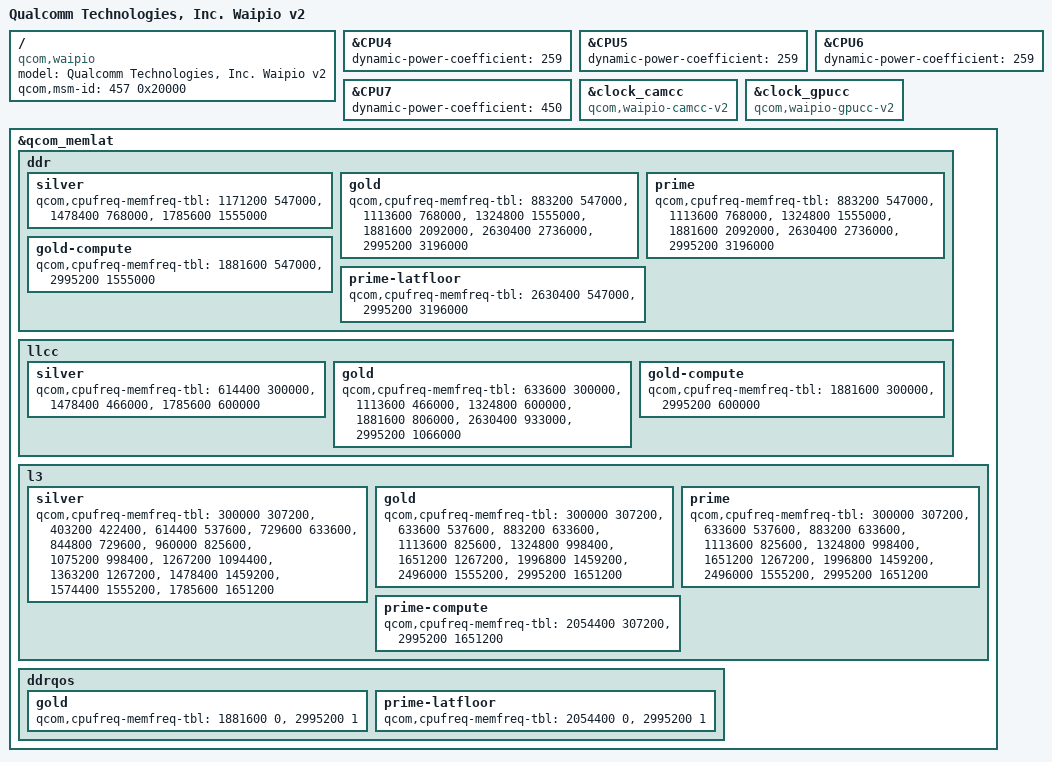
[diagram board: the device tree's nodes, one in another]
#include "waipio.dtsi"

/ {
	model = "Qualcomm Technologies, Inc. Waipio v2";
	compatible = "qcom,waipio";
	qcom,msm-id = <457 0x20000>;
};

&CPU4 {
	dynamic-power-coefficient = <259>;
};

&CPU5 {
	dynamic-power-coefficient = <259>;
};

&CPU6 {
	dynamic-power-coefficient = <259>;
};

&CPU7 {
	dynamic-power-coefficient = <450>;
};

&clock_camcc {
	compatible = "qcom,waipio-camcc-v2", "syscon";
};

&clock_gpucc {
	compatible = "qcom,waipio-gpucc-v2", "syscon";
};

&qcom_memlat {
	ddr {
		silver {
			qcom,cpufreq-memfreq-tbl =
				< 1171200  547000 >,
				< 1478400  768000 >,
				< 1785600 1555000 >;
		};

		gold {
			qcom,cpufreq-memfreq-tbl =
				<  883200  547000 >,
				< 1113600  768000 >,
				< 1324800 1555000 >,
				< 1881600 2092000 >,
				< 2630400 2736000 >,
				< 2995200 3196000 >;
		};

		prime {
			qcom,cpufreq-memfreq-tbl =
				<  883200  547000 >,
				< 1113600  768000 >,
				< 1324800 1555000 >,
				< 1881600 2092000 >,
				< 2630400 2736000 >,
				< 2995200 3196000 >;
		};

		gold-compute {
			qcom,cpufreq-memfreq-tbl =
				< 1881600  547000 >,
				< 2995200 1555000 >;
		};

		prime-latfloor {
			qcom,cpufreq-memfreq-tbl =
				< 2630400  547000 >,
				< 2995200 3196000 >;
		};
	};

	llcc {
		silver {
			qcom,cpufreq-memfreq-tbl =
				<  614400  300000 >,
				< 1478400  466000 >,
				< 1785600  600000 >;
		};

		gold {
			qcom,cpufreq-memfreq-tbl =
				<  633600  300000 >,
				< 1113600  466000 >,
				< 1324800  600000 >,
				< 1881600  806000 >,
				< 2630400  933000 >,
				< 2995200 1066000 >;
		};

		gold-compute {
			qcom,cpufreq-memfreq-tbl =
				< 1881600  300000 >,
				< 2995200  600000 >;
		};
	};

	l3 {
		silver {
			qcom,cpufreq-memfreq-tbl =
				<  300000  307200 >,
				<  403200  422400 >,
				<  614400  537600 >,
				<  729600  633600 >,
				<  844800  729600 >,
				<  960000  825600 >,
				< 1075200  998400 >,
				< 1267200 1094400 >,
				< 1363200 1267200 >,
				< 1478400 1459200 >,
				< 1574400 1555200 >,
				< 1785600 1651200 >;
		};

		gold {
			qcom,cpufreq-memfreq-tbl =
				<  300000  307200 >,
				<  633600  537600 >,
				<  883200  633600 >,
				< 1113600  825600 >,
				< 1324800  998400 >,
				< 1651200 1267200 >,
				< 1996800 1459200 >,
				< 2496000 1555200 >,
				< 2995200 1651200 >;
		};

		prime {
			qcom,cpufreq-memfreq-tbl =
				<  300000  307200 >,
				<  633600  537600 >,
				<  883200  633600 >,
				< 1113600  825600 >,
				< 1324800  998400 >,
				< 1651200 1267200 >,
				< 1996800 1459200 >,
				< 2496000 1555200 >,
				< 2995200 1651200 >;
		};

		prime-compute {
			qcom,cpufreq-memfreq-tbl =
				< 2054400  307200 >,
				< 2995200 1651200 >;
		};
	};

	ddrqos {
		gold {
			qcom,cpufreq-memfreq-tbl =
				< 1881600 0 >,
				< 2995200 1 >;
		};

		prime-latfloor {
			qcom,cpufreq-memfreq-tbl =
				< 2054400 0 >,
				< 2995200 1 >;
		};
	};
};
#include "waipio-v2-gpu.dtsi"
